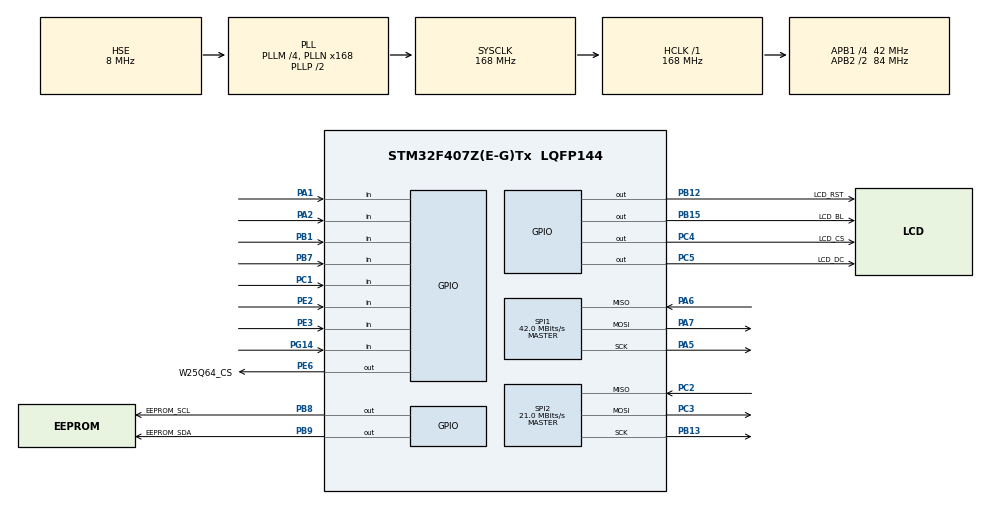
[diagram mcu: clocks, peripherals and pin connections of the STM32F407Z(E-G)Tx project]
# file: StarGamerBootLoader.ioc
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Dma.Request0=SPI2_RX
Dma.Request1=SPI2_TX
Dma.Request2=SPI1_TX
Dma.SPI1_TX.2.Direction=DMA_MEMORY_TO_PERIPH
Dma.SPI1_TX.2.FIFOMode=DMA_FIFOMODE_DISABLE
Dma.SPI1_TX.2.Instance=DMA2_Stream3
Dma.SPI1_TX.2.MemDataAlignment=DMA_MDATAALIGN_BYTE
Dma.SPI1_TX.2.MemInc=DMA_MINC_ENABLE
Dma.SPI1_TX.2.Mode=DMA_NORMAL
Dma.SPI1_TX.2.PeriphDataAlignment=DMA_PDATAALIGN_BYTE
Dma.SPI1_TX.2.PeriphInc=DMA_PINC_DISABLE
Dma.SPI1_TX.2.Priority=DMA_PRIORITY_HIGH
Dma.SPI2_RX.0.Direction=DMA_PERIPH_TO_MEMORY
Dma.SPI2_RX.0.FIFOMode=DMA_FIFOMODE_DISABLE
Dma.SPI2_RX.0.Instance=DMA1_Stream3
Dma.SPI2_RX.0.MemDataAlignment=DMA_MDATAALIGN_BYTE
Dma.SPI2_RX.0.MemInc=DMA_MINC_ENABLE
Dma.SPI2_RX.0.Mode=DMA_NORMAL
Dma.SPI2_RX.0.PeriphDataAlignment=DMA_PDATAALIGN_BYTE
Dma.SPI2_RX.0.PeriphInc=DMA_PINC_DISABLE
Dma.SPI2_RX.0.Priority=DMA_PRIORITY_MEDIUM
Dma.SPI2_TX.1.Direction=DMA_MEMORY_TO_PERIPH
Dma.SPI2_TX.1.FIFOMode=DMA_FIFOMODE_DISABLE
Dma.SPI2_TX.1.Instance=DMA1_Stream4
Dma.SPI2_TX.1.MemDataAlignment=DMA_MDATAALIGN_BYTE
Dma.SPI2_TX.1.MemInc=DMA_MINC_ENABLE
Dma.SPI2_TX.1.Mode=DMA_NORMAL
Dma.SPI2_TX.1.PeriphDataAlignment=DMA_PDATAALIGN_BYTE
Dma.SPI2_TX.1.PeriphInc=DMA_PINC_DISABLE
Dma.SPI2_TX.1.Priority=DMA_PRIORITY_MEDIUM
Mcu.Family=STM32F4
Mcu.Name=STM32F407Z(E-G)Tx
Mcu.Package=LQFP144
NVIC.DMA1_Stream3_IRQn=true\:0\:0\:false\:false\:true\:false\:true\:true
NVIC.DMA1_Stream4_IRQn=true\:0\:0\:false\:false\:true\:false\:true\:true
NVIC.DMA2_Stream3_IRQn=true\:0\:0\:false\:false\:true\:false\:true\:true
NVIC.PriorityGroup=NVIC_PRIORITYGROUP_4
NVIC.TIM8_BRK_TIM12_IRQn=true\:1\:0\:true\:false\:true\:true\:true\:true
NVIC.TIM8_UP_TIM13_IRQn=true\:1\:0\:true\:false\:true\:true\:true\:true
PA1.GPIO_PuPd=GPIO_PULLUP
PA1.Signal=GPIO_Input
PA13.Mode=Serial_Wire
PA13.Signal=SYS_JTMS-SWDIO
PA14.Mode=Serial_Wire
PA14.Signal=SYS_JTCK-SWCLK
PA2.GPIO_PuPd=GPIO_PULLUP
PA2.Signal=GPIO_Input
PA5.Mode=Full_Duplex_Master
PA5.Signal=SPI1_SCK
PA6.Mode=Full_Duplex_Master
PA6.Signal=SPI1_MISO
PA7.Mode=Full_Duplex_Master
PA7.Signal=SPI1_MOSI
PB1.GPIO_PuPd=GPIO_PULLUP
PB1.Signal=GPIO_Input
PB12.GPIO_Label=LCD_RST
PB12.PinState=GPIO_PIN_SET
PB12.Signal=GPIO_Output
PB13.Mode=Full_Duplex_Master
PB13.Signal=SPI2_SCK
PB15.GPIO_Label=LCD_BL
PB15.PinState=GPIO_PIN_SET
PB15.Signal=GPIO_Output
PB7.GPIO_PuPd=GPIO_PULLUP
PB7.Signal=GPIO_Input
PB8.GPIO_Label=EEPROM_SCL
PB8.GPIO_ModeDefaultOutputPP=GPIO_MODE_OUTPUT_OD
PB8.GPIO_PuPd=GPIO_PULLUP
PB8.PinState=GPIO_PIN_SET
PB8.Signal=GPIO_Output
PB9.GPIO_Label=EEPROM_SDA
PB9.GPIO_ModeDefaultOutputPP=GPIO_MODE_OUTPUT_OD
PB9.GPIO_PuPd=GPIO_PULLUP
PB9.PinState=GPIO_PIN_SET
PB9.Signal=GPIO_Output
PC1.GPIO_PuPd=GPIO_PULLUP
PC1.Signal=GPIO_Input
PC2.Mode=Full_Duplex_Master
PC2.Signal=SPI2_MISO
PC3.Mode=Full_Duplex_Master
PC3.Signal=SPI2_MOSI
PC4.GPIO_Label=LCD_CS
PC4.GPIO_Speed=GPIO_SPEED_FREQ_VERY_HIGH
PC4.PinState=GPIO_PIN_SET
PC4.Signal=GPIO_Output
PC5.GPIO_Label=LCD_DC
PC5.GPIO_Speed=GPIO_SPEED_FREQ_VERY_HIGH
PC5.PinState=GPIO_PIN_SET
PC5.Signal=GPIO_Output
PE2.GPIO_PuPd=GPIO_PULLUP
PE2.Signal=GPIO_Input
PE3.GPIO_PuPd=GPIO_PULLUP
PE3.Signal=GPIO_Input
PE6.GPIO_Label=W25Q64_CS
PE6.GPIO_Speed=GPIO_SPEED_FREQ_VERY_HIGH
PE6.PinState=GPIO_PIN_SET
PE6.Signal=GPIO_Output
PG14.GPIO_PuPd=GPIO_PULLUP
PG14.Signal=GPIO_Input
PH0-OSC_IN.Mode=HSE-External-Oscillator
PH0-OSC_IN.Signal=RCC_OSC_IN
PH1-OSC_OUT.Mode=HSE-External-Oscillator
PH1-OSC_OUT.Signal=RCC_OSC_OUT
ProjectManager.HeapSize=0x200
ProjectManager.StackSize=0x400
ProjectManager.TargetToolchain=MDK-ARM V5.32
RCC.48MHZClocksFreq_Value=48000000
RCC.AHBFreq_Value=168000000
RCC.APB1CLKDivider=RCC_HCLK_DIV4
RCC.APB1Freq_Value=42000000
RCC.APB1TimFreq_Value=84000000
RCC.APB2CLKDivider=RCC_HCLK_DIV2
RCC.APB2Freq_Value=84000000
RCC.APB2TimFreq_Value=168000000
RCC.CortexFreq_Value=168000000
RCC.HCLKFreq_Value=168000000
RCC.HSE_VALUE=8000000
RCC.HSI_VALUE=16000000
RCC.LSE_VALUE=32768
RCC.PLLM=4
RCC.PLLN=168
RCC.PLLQ=7
RCC.PLLSourceVirtual=RCC_PLLSOURCE_HSE
RCC.SYSCLKFreq_VALUE=168000000
RCC.SYSCLKSource=RCC_SYSCLKSOURCE_PLLCLK
RCC.VCOOutputFreq_Value=336000000
SPI1.CalculateBaudRate=42.0 MBits/s
SPI1.Direction=SPI_DIRECTION_2LINES
SPI1.Mode=SPI_MODE_MASTER
SPI1.VirtualType=VM_MASTER
SPI2.CalculateBaudRate=21.0 MBits/s
SPI2.Direction=SPI_DIRECTION_2LINES
SPI2.Mode=SPI_MODE_MASTER
SPI2.VirtualType=VM_MASTER
TIM13.Period=10-1
TIM13.Prescaler=8400-1
VP_CRC_VS_CRC.Mode=CRC_Activate
VP_TIM12_VS_ClockSourceINT.Mode=Internal
VP_TIM13_VS_ClockSourceINT.Mode=Enable_Timer
board=custom

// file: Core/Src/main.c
/* USER CODE BEGIN Header */
/**
  ******************************************************************************
  * @file           : main.c
  * @brief          : Main program body
  ******************************************************************************
  * @attention
  *
  * Copyright (c) 2026 STMicroelectronics.
  * All rights reserved.
  *
  * This software is licensed under terms that can be found in the LICENSE file
  * in the root directory of this software component.
  * If no LICENSE file comes with this software, it is provided AS-IS.
  *
  ******************************************************************************
  */
/* USER CODE END Header */
#include "main.h"

/* USER CODE BEGIN Includes */
#include "bootloader.h"
/* USER CODE END Includes */

CRC_HandleTypeDef hcrc;

SPI_HandleTypeDef hspi1;
SPI_HandleTypeDef hspi2;
DMA_HandleTypeDef hdma_spi1_tx;
DMA_HandleTypeDef hdma_spi2_rx;
DMA_HandleTypeDef hdma_spi2_tx;

TIM_HandleTypeDef htim12;
TIM_HandleTypeDef htim13;

void SystemClock_Config(void);
static void MX_GPIO_Init(void);
static void MX_DMA_Init(void);
static void MX_SPI1_Init(void);
static void MX_SPI2_Init(void);
static void MX_CRC_Init(void);
static void MX_TIM12_Init(void);
static void MX_TIM13_Init(void);

/* USER CODE BEGIN 0 */

void SystemClock_SwitchToHSI(void)
{
    __HAL_RCC_SYSCLK_CONFIG(RCC_SYSCLKSOURCE_HSI);

    while (__HAL_RCC_GET_SYSCLK_SOURCE() != RCC_SYSCLKSOURCE_STATUS_HSI) {}
}

void SystemClock_SwitchToPLL(void)
{
    __HAL_RCC_SYSCLK_CONFIG(RCC_SYSCLKSOURCE_PLLCLK);

    while (__HAL_RCC_GET_SYSCLK_SOURCE() != RCC_SYSCLKSOURCE_STATUS_PLLCLK) {}
}

/* USER CODE END 0 */

int main(void)
{

  /* MCU Configuration--------------------------------------------------------*/

  /* Reset of all peripherals, Initializes the Flash interface and the Systick. */
  HAL_Init();

  /* Configure the system clock */
  SystemClock_Config();

  /* Initialize all configured peripherals */
  MX_GPIO_Init();
  MX_DMA_Init();
  MX_SPI1_Init();
  MX_SPI2_Init();
  MX_CRC_Init();
  MX_TIM12_Init();
  MX_TIM13_Init();
  /* USER CODE BEGIN 2 */
  if (HAL_TIM_Base_Start_IT(&htim13) != HAL_OK)
  {
    Error_Handler();
  }
  Bootloader_Run();
  /* USER CODE END 2 */

  /* Infinite loop */
  while (1)
  {

  }
}

void SystemClock_Config(void)
{
  RCC_OscInitTypeDef RCC_OscInitStruct = {0};
  RCC_ClkInitTypeDef RCC_ClkInitStruct = {0};

  /** Configure the main internal regulator output voltage
  */
  __HAL_RCC_PWR_CLK_ENABLE();
  __HAL_PWR_VOLTAGESCALING_CONFIG(PWR_REGULATOR_VOLTAGE_SCALE1);
	SystemClock_SwitchToHSI();

  /** Initializes the RCC Oscillators according to the specified parameters
  * in the RCC_OscInitTypeDef structure.
  */
  RCC_OscInitStruct.OscillatorType = RCC_OSCILLATORTYPE_HSE;
  RCC_OscInitStruct.HSEState = RCC_HSE_ON;
  RCC_OscInitStruct.PLL.PLLState = RCC_PLL_ON;
  RCC_OscInitStruct.PLL.PLLSource = RCC_PLLSOURCE_HSE;
  RCC_OscInitStruct.PLL.PLLM = 4;
  RCC_OscInitStruct.PLL.PLLN = 168;
  RCC_OscInitStruct.PLL.PLLP = RCC_PLLP_DIV2;
  RCC_OscInitStruct.PLL.PLLQ = 7;
  if (HAL_RCC_OscConfig(&RCC_OscInitStruct) != HAL_OK)
  {
    Error_Handler();
  }

  /** Initializes the CPU, AHB and APB buses clocks
  */
  RCC_ClkInitStruct.ClockType = RCC_CLOCKTYPE_HCLK|RCC_CLOCKTYPE_SYSCLK
                              |RCC_CLOCKTYPE_PCLK1|RCC_CLOCKTYPE_PCLK2;
  RCC_ClkInitStruct.SYSCLKSource = RCC_SYSCLKSOURCE_PLLCLK;
  RCC_ClkInitStruct.AHBCLKDivider = RCC_SYSCLK_DIV1;
  RCC_ClkInitStruct.APB1CLKDivider = RCC_HCLK_DIV4;
  RCC_ClkInitStruct.APB2CLKDivider = RCC_HCLK_DIV2;

  if (HAL_RCC_ClockConfig(&RCC_ClkInitStruct, FLASH_LATENCY_5) != HAL_OK)
  {
    Error_Handler();
  }

	SystemClock_SwitchToPLL();
}

static void MX_CRC_Init(void)
{

  hcrc.Instance = CRC;
  if (HAL_CRC_Init(&hcrc) != HAL_OK)
  {
    Error_Handler();
  }

}

static void MX_SPI1_Init(void)
{

  /* SPI1 parameter configuration*/
  hspi1.Instance = SPI1;
  hspi1.Init.Mode = SPI_MODE_MASTER;
  hspi1.Init.Direction = SPI_DIRECTION_2LINES;
  hspi1.Init.DataSize = SPI_DATASIZE_8BIT;
  hspi1.Init.CLKPolarity = SPI_POLARITY_LOW;
  hspi1.Init.CLKPhase = SPI_PHASE_1EDGE;
  hspi1.Init.NSS = SPI_NSS_SOFT;
  hspi1.Init.BaudRatePrescaler = SPI_BAUDRATEPRESCALER_2;
  hspi1.Init.FirstBit = SPI_FIRSTBIT_MSB;
  hspi1.Init.TIMode = SPI_TIMODE_DISABLE;
  hspi1.Init.CRCCalculation = SPI_CRCCALCULATION_DISABLE;
  hspi1.Init.CRCPolynomial = 10;
  if (HAL_SPI_Init(&hspi1) != HAL_OK)
  {
    Error_Handler();
  }

}

static void MX_SPI2_Init(void)
{

  /* SPI2 parameter configuration*/
  hspi2.Instance = SPI2;
  hspi2.Init.Mode = SPI_MODE_MASTER;
  hspi2.Init.Direction = SPI_DIRECTION_2LINES;
  hspi2.Init.DataSize = SPI_DATASIZE_8BIT;
  hspi2.Init.CLKPolarity = SPI_POLARITY_LOW;
  hspi2.Init.CLKPhase = SPI_PHASE_1EDGE;
  hspi2.Init.NSS = SPI_NSS_SOFT;
  hspi2.Init.BaudRatePrescaler = SPI_BAUDRATEPRESCALER_2;
  hspi2.Init.FirstBit = SPI_FIRSTBIT_MSB;
  hspi2.Init.TIMode = SPI_TIMODE_DISABLE;
  hspi2.Init.CRCCalculation = SPI_CRCCALCULATION_DISABLE;
  hspi2.Init.CRCPolynomial = 10;
  if (HAL_SPI_Init(&hspi2) != HAL_OK)
  {
    Error_Handler();
  }

}

static void MX_TIM12_Init(void)
{

  TIM_ClockConfigTypeDef sClockSourceConfig = {0};

  htim12.Instance = TIM12;
  htim12.Init.Prescaler = 0;
  htim12.Init.CounterMode = TIM_COUNTERMODE_UP;
  htim12.Init.Period = 65535;
  htim12.Init.ClockDivision = TIM_CLOCKDIVISION_DIV1;
  htim12.Init.AutoReloadPreload = TIM_AUTORELOAD_PRELOAD_DISABLE;
  if (HAL_TIM_Base_Init(&htim12) != HAL_OK)
  {
    Error_Handler();
  }
  sClockSourceConfig.ClockSource = TIM_CLOCKSOURCE_INTERNAL;
  if (HAL_TIM_ConfigClockSource(&htim12, &sClockSourceConfig) != HAL_OK)
  {
    Error_Handler();
  }

}

static void MX_TIM13_Init(void)
{

  htim13.Instance = TIM13;
  htim13.Init.Prescaler = 8399;
  htim13.Init.CounterMode = TIM_COUNTERMODE_UP;
  htim13.Init.Period = 9;
  htim13.Init.ClockDivision = TIM_CLOCKDIVISION_DIV1;
  htim13.Init.AutoReloadPreload = TIM_AUTORELOAD_PRELOAD_DISABLE;
  if (HAL_TIM_Base_Init(&htim13) != HAL_OK)
  {
    Error_Handler();
  }

}

static void MX_DMA_Init(void)
{

  /* DMA controller clock enable */
  __HAL_RCC_DMA1_CLK_ENABLE();
  __HAL_RCC_DMA2_CLK_ENABLE();

  /* DMA interrupt init */
  /* DMA1_Stream3_IRQn interrupt configuration */
  HAL_NVIC_SetPriority(DMA1_Stream3_IRQn, 0, 0);
  HAL_NVIC_EnableIRQ(DMA1_Stream3_IRQn);
  /* DMA1_Stream4_IRQn interrupt configuration */
  HAL_NVIC_SetPriority(DMA1_Stream4_IRQn, 0, 0);
  HAL_NVIC_EnableIRQ(DMA1_Stream4_IRQn);
  /* DMA2_Stream3_IRQn interrupt configuration */
  HAL_NVIC_SetPriority(DMA2_Stream3_IRQn, 0, 0);
  HAL_NVIC_EnableIRQ(DMA2_Stream3_IRQn);

}

static void MX_GPIO_Init(void)
{
  GPIO_InitTypeDef GPIO_InitStruct = {0};

  /* GPIO Ports Clock Enable */
  __HAL_RCC_GPIOE_CLK_ENABLE();
  __HAL_RCC_GPIOH_CLK_ENABLE();
  __HAL_RCC_GPIOC_CLK_ENABLE();
  __HAL_RCC_GPIOA_CLK_ENABLE();
  __HAL_RCC_GPIOB_CLK_ENABLE();
  __HAL_RCC_GPIOG_CLK_ENABLE();

  /*Configure GPIO pin Output Level */
  HAL_GPIO_WritePin(GPIOE, GPIO_PIN_6, GPIO_PIN_SET);

  /*Configure GPIO pin Output Level */
  HAL_GPIO_WritePin(GPIOC, GPIO_PIN_4|GPIO_PIN_5, GPIO_PIN_SET);

  /*Configure GPIO pin Output Level */
  HAL_GPIO_WritePin(GPIOB, GPIO_PIN_8|GPIO_PIN_9|GPIO_PIN_12|GPIO_PIN_15, GPIO_PIN_SET);

  /*Configure GPIO pins : PE2 PE3 */
  GPIO_InitStruct.Pin = GPIO_PIN_2|GPIO_PIN_3;
  GPIO_InitStruct.Mode = GPIO_MODE_INPUT;
  GPIO_InitStruct.Pull = GPIO_PULLUP;
  HAL_GPIO_Init(GPIOE, &GPIO_InitStruct);

  /*Configure GPIO pin : PC1 */
  GPIO_InitStruct.Pin = GPIO_PIN_1;
  GPIO_InitStruct.Mode = GPIO_MODE_INPUT;
  GPIO_InitStruct.Pull = GPIO_PULLUP;
  HAL_GPIO_Init(GPIOC, &GPIO_InitStruct);

  /*Configure GPIO pins : PA1 PA2 */
  GPIO_InitStruct.Pin = GPIO_PIN_1|GPIO_PIN_2;
  GPIO_InitStruct.Mode = GPIO_MODE_INPUT;
  GPIO_InitStruct.Pull = GPIO_PULLUP;
  HAL_GPIO_Init(GPIOA, &GPIO_InitStruct);

  /*Configure GPIO pins : PB1 PB7 */
  GPIO_InitStruct.Pin = GPIO_PIN_1|GPIO_PIN_7;
  GPIO_InitStruct.Mode = GPIO_MODE_INPUT;
  GPIO_InitStruct.Pull = GPIO_PULLUP;
  HAL_GPIO_Init(GPIOB, &GPIO_InitStruct);

  /*Configure GPIO pin : PG14 */
  GPIO_InitStruct.Pin = GPIO_PIN_14;
  GPIO_InitStruct.Mode = GPIO_MODE_INPUT;
  GPIO_InitStruct.Pull = GPIO_PULLUP;
  HAL_GPIO_Init(GPIOG, &GPIO_InitStruct);

  /*Configure GPIO pin : PE6 */
  GPIO_InitStruct.Pin = GPIO_PIN_6;
  GPIO_InitStruct.Mode = GPIO_MODE_OUTPUT_PP;
  GPIO_InitStruct.Pull = GPIO_NOPULL;
  GPIO_InitStruct.Speed = GPIO_SPEED_FREQ_VERY_HIGH;
  HAL_GPIO_Init(GPIOE, &GPIO_InitStruct);

  /*Configure GPIO pins : PC4 PC5 */
  GPIO_InitStruct.Pin = GPIO_PIN_4|GPIO_PIN_5;
  HAL_GPIO_Init(GPIOC, &GPIO_InitStruct);

  /*Configure GPIO pins : PB12 PB15 */
  GPIO_InitStruct.Pin = GPIO_PIN_12|GPIO_PIN_15;
  HAL_GPIO_Init(GPIOB, &GPIO_InitStruct);

  /*Configure GPIO pins : PB8 PB9 */
  GPIO_InitStruct.Pin = GPIO_PIN_8|GPIO_PIN_9;
  GPIO_InitStruct.Mode = GPIO_MODE_OUTPUT_OD;
  GPIO_InitStruct.Pull = GPIO_PULLUP;
  GPIO_InitStruct.Speed = GPIO_SPEED_FREQ_HIGH;
  HAL_GPIO_Init(GPIOB, &GPIO_InitStruct);

}

void Error_Handler(void)
{
  __disable_irq();
  while (1)
  {
  }
}
